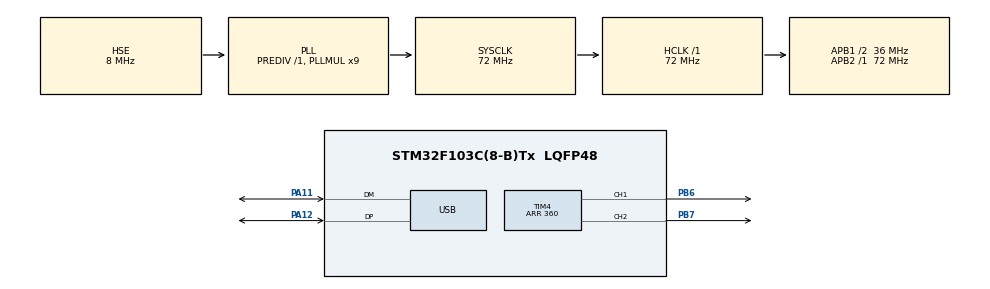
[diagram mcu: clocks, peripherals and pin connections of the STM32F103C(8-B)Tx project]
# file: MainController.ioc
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Dma.Request0=TIM3_CH4/UP
Dma.TIM3_CH4/UP.0.Direction=DMA_MEMORY_TO_PERIPH
Dma.TIM3_CH4/UP.0.Instance=DMA1_Channel3
Dma.TIM3_CH4/UP.0.MemDataAlignment=DMA_MDATAALIGN_HALFWORD
Dma.TIM3_CH4/UP.0.MemInc=DMA_MINC_ENABLE
Dma.TIM3_CH4/UP.0.Mode=DMA_CIRCULAR
Dma.TIM3_CH4/UP.0.PeriphDataAlignment=DMA_PDATAALIGN_HALFWORD
Dma.TIM3_CH4/UP.0.PeriphInc=DMA_PINC_DISABLE
Dma.TIM3_CH4/UP.0.Priority=DMA_PRIORITY_VERY_HIGH
FREERTOS.Tasks01=defaultTask,24,128,StartDefaultTask,Default,NULL,Dynamic,NULL,NULL;RxTxUSBTask,8,128,USBTask,As external,NULL,Dynamic,NULL,NULL
Mcu.Family=STM32F1
Mcu.Name=STM32F103C(8-B)Tx
Mcu.Package=LQFP48
NVIC.DMA1_Channel3_IRQn=true\:5\:0\:false\:false\:true\:true\:false\:true\:true
NVIC.PriorityGroup=NVIC_PRIORITYGROUP_4
NVIC.USB_LP_CAN1_RX0_IRQn=true\:5\:0\:false\:false\:true\:true\:false\:true\:true
PA11.Mode=Device
PA11.Signal=USB_DM
PA12.Mode=Device
PA12.Signal=USB_DP
PA13.Mode=Serial_Wire
PA13.Signal=SYS_JTMS-SWDIO
PA14.Mode=Serial_Wire
PA14.Signal=SYS_JTCK-SWCLK
PB6.Signal=S_TIM4_CH1
PB7.Signal=S_TIM4_CH2
PD0-OSC_IN.Mode=HSE-External-Oscillator
PD0-OSC_IN.Signal=RCC_OSC_IN
PD1-OSC_OUT.Mode=HSE-External-Oscillator
PD1-OSC_OUT.Signal=RCC_OSC_OUT
ProjectManager.HeapSize=0x200
ProjectManager.StackSize=0x400
ProjectManager.TargetToolchain=EWARM V8.32
RCC.AHBFreq_Value=72000000
RCC.APB1CLKDivider=RCC_HCLK_DIV2
RCC.APB1Freq_Value=36000000
RCC.APB1TimFreq_Value=72000000
RCC.APB2Freq_Value=72000000
RCC.APB2TimFreq_Value=72000000
RCC.HCLKFreq_Value=72000000
RCC.PLLMUL=RCC_PLL_MUL9
RCC.PLLSourceVirtual=RCC_PLLSOURCE_HSE
RCC.SYSCLKFreq_VALUE=72000000
RCC.SYSCLKSource=RCC_SYSCLKSOURCE_PLLCLK
RCC.USBFreq_Value=48000000
RCC.USBPrescaler=RCC_USBCLKSOURCE_PLL_DIV1_5
SH.S_TIM4_CH1.0=TIM4_CH1,PWM Generation1 CH1
SH.S_TIM4_CH2.0=TIM4_CH2,PWM Generation2 CH2
TIM3.AutoReloadPreload=TIM_AUTORELOAD_PRELOAD_ENABLE
TIM3.Channel-Output\ Compare4\ No\ Output=TIM_CHANNEL_4
TIM3.Period=375
TIM4.Channel-PWM\ Generation1\ CH1=TIM_CHANNEL_1
TIM4.Channel-PWM\ Generation2\ CH2=TIM_CHANNEL_2
TIM4.Period=360
TIM4.Pulse-PWM\ Generation1\ CH1=256
TIM4.Pulse-PWM\ Generation2\ CH2=768
USB_DEVICE.CLASS_NAME_FS=CDC
USB_DEVICE.MANUFACTURER_STRING=Tluwes
USB_DEVICE.PRODUCT_STRING_CDC_FS=ADC Stand
USB_DEVICE.VirtualMode=Cdc
USB_DEVICE.VirtualModeFS=Cdc_FS
VP_FREERTOS_VS_CMSIS_V2.Mode=CMSIS_V2
VP_TIM3_VS_ClockSourceINT.Mode=Internal
VP_TIM3_VS_no_output4.Mode=Output Compare4 No Output
VP_TIM4_VS_ClockSourceINT.Mode=Internal
VP_USB_DEVICE_VS_USB_DEVICE_CDC_FS.Mode=CDC_FS
board=custom

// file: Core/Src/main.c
/* USER CODE BEGIN Header */
/**
  ******************************************************************************
  * @file           : main.c
  * @brief          : Main program body
  ******************************************************************************
  * @attention
  *
  * Copyright (c) 2024 STMicroelectronics.
  * All rights reserved.
  *
  * This software is licensed under terms that can be found in the LICENSE file
  * in the root directory of this software component.
  * If no LICENSE file comes with this software, it is provided AS-IS.
  *
  ******************************************************************************
  */
/* USER CODE END Header */
#include "main.h"
#include "cmsis_os.h"
#include "dma.h"
#include "tim.h"
#include "usb_device.h"
#include "gpio.h"

void SystemClock_Config(void);
void MX_FREERTOS_Init(void);

int main(void)
{

  /* MCU Configuration--------------------------------------------------------*/

  /* Reset of all peripherals, Initializes the Flash interface and the Systick. */
  HAL_Init();

  /* USER CODE BEGIN Init */
	InitSettings();
  /* USER CODE END Init */

  /* Configure the system clock */
  SystemClock_Config();

  /* Initialize all configured peripherals */
  MX_GPIO_Init();
  MX_DMA_Init();
  MX_TIM4_Init();
  MX_TIM3_Init();

  /* Init scheduler */
  osKernelInitialize();  /* Call init function for freertos objects (in freertos.c) */
  MX_FREERTOS_Init();

  /* Start scheduler */
  osKernelStart();

  /* We should never get here as control is now taken by the scheduler */
  /* Infinite loop */
  while (1)
  {

  }
}

void SystemClock_Config(void)
{
  RCC_OscInitTypeDef RCC_OscInitStruct = {0};
  RCC_ClkInitTypeDef RCC_ClkInitStruct = {0};
  RCC_PeriphCLKInitTypeDef PeriphClkInit = {0};

  /** Initializes the RCC Oscillators according to the specified parameters
  * in the RCC_OscInitTypeDef structure.
  */
  RCC_OscInitStruct.OscillatorType = RCC_OSCILLATORTYPE_HSE;
  RCC_OscInitStruct.HSEState = RCC_HSE_ON;
  RCC_OscInitStruct.HSEPredivValue = RCC_HSE_PREDIV_DIV1;
  RCC_OscInitStruct.HSIState = RCC_HSI_ON;
  RCC_OscInitStruct.PLL.PLLState = RCC_PLL_ON;
  RCC_OscInitStruct.PLL.PLLSource = RCC_PLLSOURCE_HSE;
  RCC_OscInitStruct.PLL.PLLMUL = RCC_PLL_MUL9;
  if (HAL_RCC_OscConfig(&RCC_OscInitStruct) != HAL_OK)
  {
    Error_Handler();
  }

  /** Initializes the CPU, AHB and APB buses clocks
  */
  RCC_ClkInitStruct.ClockType = RCC_CLOCKTYPE_HCLK|RCC_CLOCKTYPE_SYSCLK
                              |RCC_CLOCKTYPE_PCLK1|RCC_CLOCKTYPE_PCLK2;
  RCC_ClkInitStruct.SYSCLKSource = RCC_SYSCLKSOURCE_PLLCLK;
  RCC_ClkInitStruct.AHBCLKDivider = RCC_SYSCLK_DIV1;
  RCC_ClkInitStruct.APB1CLKDivider = RCC_HCLK_DIV2;
  RCC_ClkInitStruct.APB2CLKDivider = RCC_HCLK_DIV1;

  if (HAL_RCC_ClockConfig(&RCC_ClkInitStruct, FLASH_LATENCY_2) != HAL_OK)
  {
    Error_Handler();
  }
  PeriphClkInit.PeriphClockSelection = RCC_PERIPHCLK_USB;
  PeriphClkInit.UsbClockSelection = RCC_USBCLKSOURCE_PLL_DIV1_5;
  if (HAL_RCCEx_PeriphCLKConfig(&PeriphClkInit) != HAL_OK)
  {
    Error_Handler();
  }
}

void Error_Handler(void)
{
  __disable_irq();
  while (1)
  {
  }
}
